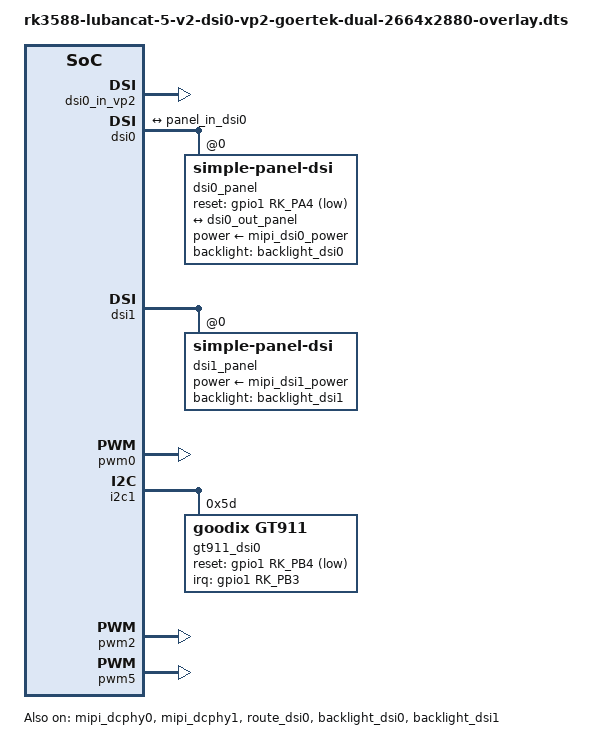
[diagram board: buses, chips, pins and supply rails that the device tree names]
/dts-v1/;
/plugin/;

#include <dt-bindings/gpio/gpio.h>
#include <dt-bindings/pinctrl/rockchip.h>
#include <dt-bindings/display/drm_mipi_dsi.h>
#include <dt-bindings/interrupt-controller/irq.h>

/ {
	fragment@0 {
		target = <&mipi_dcphy0>;

		__overlay__ {
			status = "okay";
		};
	};

	fragment@1 {
		target = <&mipi_dcphy1>;

		__overlay__ {
			status = "okay";
		};
	};

	fragment@2 {
		target = <&route_dsi0>;

		__overlay__ {
			status = "okay";
			connect = <&vp2_out_dsi0>;
		};
	};

	fragment@3 {
		target = <&route_dsi1>;

		__overlay__ {
			status = "disabled";
		};
	};

	fragment@4 {
		target = <&dsi0_in_vp2>;

		__overlay__ {
			status = "okay";
		};
	};

	fragment@5 {
		target = <&dsi1_in_vp3>;

		__overlay__ {
			status = "disabled";
		};
	};

	fragment@6 {
		target = <&dsi0>;

		__overlay__ {
			status = "okay";
			#address-cells = <1>;
			#size-cells = <0>;
			rockchip,dual-channel = <&dsi1>;
			rockchip,lane-rate = <1250000>;

			dsi0_panel: panel@0 {
				status = "okay";
				compatible = "simple-panel-dsi";
				reg = <0>;
				backlight = <&backlight_dsi0>;
				power-supply = <&mipi_dsi0_power>;
				reset-gpios = <&gpio1 RK_PA4 GPIO_ACTIVE_LOW>;

				enable-delay-ms = <35>;
				prepare-delay-ms = <6>;
				reset-delay-ms = <2000>;
				init-delay-ms = <3000>;
				unprepare-delay-ms = <0>;
				disable-delay-ms = <20>;

				dsi,flags = <(MIPI_DSI_MODE_VIDEO |
					       MIPI_DSI_MODE_VIDEO_BURST |
					       MIPI_DSI_CLOCK_NON_CONTINUOUS |
					       MIPI_DSI_MODE_LPM)>;
				dsi,format = <MIPI_DSI_FMT_RGB888>;
				dsi,lanes = <8>;

				panel-init-sequence = [
					39 00 02 b0 00
					39 00 02 ff 00
					39 00 5f f5 12 00 00 89 30 80 0f 00 0d e0 00 18 03 78 03 78 02 00 02 e1 00 20 02 b9 00 0c 00 0d 04 86 02 94 18 00 10 f0 03 0c 20 00 06 0b 0b 33 0e 1c 2a 38 46 54 62 69 70 77 79 7b 7d 7e 01 02 01 00 09 40 09 be 19 fc 19 fa 19 f8 1a 38 1a 78 1a b6 2a b6 2a f4 2a f4 4b 34 63 74 00 00 00 00 00 00
					39 00 5f f6 11 00 00 ab 10 a0 0a 00 05 a0 00 20 02 d0 03 84 01 9a 02 68 00 19 02 d9 00 0e 00 0f 03 df 02 eb 16 00 10 ec 07 10 20 00 06 0f 0f 33 0e 1c 2a 38 46 54 62 69 70 77 79 7b 7d 7e 01 c2 22 00 2a 40 2a be 3a fc 3a fa 3a f8 3b 38 3b 78 3b 76 4b b6 4b b6 4b f4 63 f4 7c 34 00 00 00 00 00 00
					39 00 5f f7 11 00 00 89 10 80 0a 00 05 a0 00 20 02 d0 02 d0 02 00 02 68 00 20 03 87 00 0a 00 0c 03 19 02 63 18 00 10 f0 03 0c 20 00 06 0b 0b 33 0e 1c 2a 38 46 54 62 69 70 77 79 7b 7d 7e 01 02 01 00 09 40 09 be 19 fc 19 fa 19 f8 1a 38 1a 78 1a b6 2a f6 2b 34 2b 74 3b 74 6b f4 00 00 00 00 00 00
					39 00 5f f8 11 00 00 ab 10 a0 0a 00 05 a0 00 20 02 d0 03 84 01 9a 02 68 00 19 02 d9 00 0e 00 0f 03 df 02 eb 16 00 10 ec 07 10 20 00 06 0f 0f 33 0e 1c 2a 38 46 54 62 69 70 77 79 7b 7d 7e 01 c2 22 00 2a 40 2a be 3a fc 3a fa 3a f8 3b 38 3b 78 3b 76 4b b6 4b b6 4b f4 63 f4 7c 34 00 00 00 00 00 00
					39 00 1c b1 00 18 19 00 18 18 00 18 18 00 18 18 00 18 18 00 18 18 00 18 18 00 18 18 00 18 19
					39 00 13 b2 0f 00 0f 00 0f 00 0f 00 0f 00 0f 00 0f 00 0f 00 0f 00
					39 00 03 b4 00 ba
					39 00 08 b5 11 11 00 01 25 00 eb
					39 00 02 b7 93
					39 00 02 b8 06
					39 00 02 ba 8c
					39 00 02 bb 01
					39 00 03 bc 00 00
					39 00 15 c7 00 00 ff ff 01 03 ff 03 ff 03 ff 00 00 00 00 00 00 00 00 00
					39 00 09 c8 10 32 54 76 98 ba dc 0e
					39 00 02 ff 01
					39 00 15 b1 30 6c 06 ff ff 00 00 48 a3 6b 00 92 03 1a d0 09 00 00 00 08
					39 00 04 b2 00 00 00
					39 00 bc b5 11 11 10 33 33 33 33 33 ff ff ff 6c 00 00 ff ff ff ff f0 01 00 fb 00 00 00 aa fa 1b 03 20 00 40 00 00 03 10 51 51 10 04 10 03 11 10 04 10 03 10 04 10 03 11 10 03 10 03 00 00 00 00 10 01 10 01 00 00 00 1f ff 00 00 10 01 10 01 00 00 00 1f ff 00 00 00 10 01 10 01 00 80 00 1f ff 00 00 00 10 01 10 01 00 00 00 1f ff 00 00 00 10 01 10 01 00 00 00 1f ff 00 00 10 01 10 01 00 00 00 1f ff 01 00 10 01 10 01 00 00 00 00 00 00 00 10 01 10 01 00 00 00 00 00 00 00 00 00 02 00 00 02 00 00 02 00 00 02 00 00 02 00 00 02 00 00 02 00 00 02 00 00 00 00 00 00 00 00 00 00 00 00
					39 00 55 b6 b0 00 00 00 00 00 80 04 0a f0 01 00 00 20 20 00 00 00 00 00 00 00 00 00 00 00 03 05 84 97 8b 00 00 21 00 21 00 21 00 21 00 21 00 21 00 40 00 00 00 00 00 00 00 00 00 00 00 00 00 00 00 00 00 00 00 00 00 00 00 00 03 28 00 14 00 14 00 14 00 14 00 14 00 14
					39 00 5d b7 00 00 00 02 00 00 40 05 00 00 88 88 88 88 00 00 00 00 00 00 00 00 00 00 00 00 00 00 00 00 00 00 00 00 00 00 00 00 00 a8 a8 a8 a8 a8 a8 a8 a8 00 ff aa 00 09 10 00 00 00 00 00 00 00 11 11 11 11 11 11 11 11 11 11 11 11 a0 00 00 10 09 c4 01 0a 0a 03 c9 00 00 00 06 7c 28 06 7c 28
					39 00 77 ba 00 00 00 00 20 02 6c 10 00 00 00 00 00 00 00 6c 10 00 00 00 00 01 50 17 00 10 00 00 00 00 00 00 00 00 00 00 00 00 00 00 00 00 00 00 00 00 00 00 00 0f ff 00 00 00 00 00 00 00 0f 10 00 10 00 00 00 00 01 b3 20 00 10 00 00 00 00 02 00 00 02 00 00 02 00 00 02 00 00 02 00 00 02 00 00 02 00 00 02 00 00 00 00 00 00 00 00 00 00 00 00 00 00 00 00 00 00 00 00 00
					39 00 78 bb 3f fd 00 1f 3f f0 00 03 3f fc 00 0f 3f fc 00 0f 3f fc 00 0f 3f fc 00 0f 3f f0 00 03 3f fc 00 0f 00 00 00 00 00 00 00 00 00 00 00 00 00 00 00 00 00 00 00 00 00 3f fc 00 0f 3f fc 00 0f 3f fc 00 0f 3f fc 00 0f 3f fc 00 0f 3f fc 00 0f 3f fc 00 0f 3f fd 15 5f 3f fc 00 0f 3f fc 00 0f 3f fc 00 0f 3f fc 00 0f 03 c0 00 0f 00 00 48 00 00 01 00 09 3f fc 00 0f 00 00
					39 00 21 be 00 00 00 00 00 07 00 00 00 00 00 00 00 00 00 00 50 aa aa aa aa aa aa 90 00 aa aa aa aa aa aa 90
					39 00 8c bf 46 48 4a 4c 4e 50 02 06 0a 0e 12 16 1a 1e 22 2a 01 01 01 01 3c 41 00 00 01 01 33 00 01 01 46 48 4a 4c 4e 50 02 06 0a 0e 12 16 1a 1e 22 2a 01 01 01 01 3c 41 00 00 01 01 33 01 01 01 00 00 00 00 00 00 00 00 00 00 00 00 00 00 00 00 00 00 00 00 00 00 00 00 ff ff ff ff ff ff ff 0f 3f 00 01 00 00 08 c0 0f 00 20 00 00 00 08 00 00 80 00 00 00 00 00 00 00 00 00 00 00 00 00 00 00 00 00 00 00 00 00 00 00 00 00 00 00 00 00 00
					39 00 69 c0 03 e8 03 e8 03 e8 00 07 00 07 00 07 03 e8 03 e8 03 e8 00 07 00 07 00 07 03 e8 03 e8 03 e8 00 07 00 07 00 07 03 e8 03 e8 03 e8 00 07 00 07 00 07 00 00 00 29 00 17 00 17 00 17 00 17 00 17 00 17 00 00 00 00 00 00 00 00 00 00 00 00 00 00 00 2b 00 16 00 16 00 16 00 16 00 16 00 08 00 00 00 00 00 00 00 00 00 00 00 00
					39 00 54 c2 00 00 bc 00 97 00 97 00 00 00 00 00 00 00 00 00 00 00 5e 00 5e 00 5e 00 5e 00 5e 00 5e 00 5e 00 5e 00 9b 00 9b 00 a3 00 ab 00 31 00 bc 00 31 00 bc 00 0e 00 31 00 0e 00 31 00 84 00 b4 00 00 00 9f 00 00 1f ff 00 00 1f ff 00 26 00 84 00 5e 00 5e 00 00
					39 00 ac c3 02 00 14 02 00 14 02 00 14 02 00 14 02 00 14 02 00 14 00 00 12 00 00 12 00 00 12 00 00 12 00 00 12 00 00 12 06 00 24 06 00 24 06 00 24 06 00 24 06 00 24 06 00 24 03 00 28 03 00 28 03 00 28 03 00 28 03 00 28 03 00 28 00 00 00 60 00 24 00 82 00 58 00 99 00 4c 00 aa 00 2e 00 9f 00 26 00 58 00 29 00 84 00 00 00 00 00 00 00 02 00 19 00 21 00 a3 00 ab 00 00 00 00 00 00 00 00 00 00 00 00 00 00 00 00 00 00 00 00 00 00 00 00 00 00 00 00 00 00 00 00 00 00 00 00 00 00 00 00 00 00 00 00 10 00 00 00 00 00 00 00 00 00 00
					39 00 2b c4 00 00 00 00 00 00 5e 00 5f 00 7e 00 81 00 57 00 57 00 4b 00 4b 00 28 00 03 00 5a 00 00 00 5e 00 5e 00 5e 00 5e f0 ff ff 7f e7
					39 00 0b c5 00 00 00 00 00 00 00 00 08 00
					39 00 36 c7 51 c8 c8 c8 c8 c8 c8 c8 c8 c8 00 ff ff ff ff ff ff ff ff ff 4a 48 46 44 42 40 3e 3c 3a 00 ff ff ff ff ff ff ff ff ff ff ff ff ff ff ff ff ff ff 04 04 42 00 88
					39 00 44 c8 00 1c fc fc fc 00 00 00 00 00 00 00 00 00 00 00 00 00 00 00 00 00 00 00 00 00 00 00 00 00 00 00 00 00 00 00 00 00 00 00 00 00 00 00 00 00 00 00 00 00 00 00 00 00 00 00 00 00 00 00 00 00 00 00 00 08 08
					39 00 44 c9 00 1c fc fc fc 00 00 00 00 00 00 00 00 00 00 00 00 00 00 00 00 00 00 00 00 00 00 00 00 00 00 00 00 00 00 00 00 00 00 00 00 00 00 00 00 00 00 00 00 00 00 00 00 00 00 00 00 00 00 00 00 00 00 00 00 08 08
					39 00 44 ca c0 1c fc fc fc 00 00 00 00 00 00 00 00 00 00 00 00 00 00 00 00 00 00 00 00 00 00 00 00 00 00 00 00 00 00 00 00 00 00 00 00 00 00 00 00 00 00 00 00 00 00 00 00 00 00 00 00 00 00 00 00 00 00 00 00 08 08
					39 00 3d cb 91 cf ed 52 54 04 32 33 ff ff ff ff ff ff ff ff ff f8 00 00 00 01 01 02 02 03 03 04 04 04 04 04 04 04 04 04 04 04 04 04 0a 0b 0b 0c 0c 0d 0d 0e 0e 0e 0e 0e 0e 0e 0e 0e 0e 0e 0e 0e
					39 00 25 cc 8d e0 01 32 32 32 32 32 32 32 32 32 00 49 81 2c 00 40 00 08 0c 00 40 40 00 00 00 00 00 00 00 02 00 ff ff ff
					39 00 0f ce 00 00 00 00 00 00 00 00 00 00 00 00 00 00
					39 00 13 cf 88 24 00 00 00 00 00 00 00 00 00 00 00 00 00 00 00 00
					39 00 b2 d1 0c ff ff ff 00 03 0c 1e 38 5b 89 c0 ff 00 03 0c 1e 38 5b 89 c0 ff 00 03 0c 1e 38 5b 89 c0 ff ff ff ff ff ff ff ff ff ff ff ff ff ff ff ff ff ff ff ff ff ff ff ff ff ff ff ff ff ff ff ff ff ff ff ff 80 80 80 80 80 80 80 80 80 80 80 80 80 80 80 80 80 80 80 80 80 80 80 80 80 80 80 80 80 80 80 80 80 80 80 80 80 80 80 80 80 80 80 80 80 80 80 80 80 80 80 00 00 00 00 00 00 00 00 00 00 00 00 00 00 00 00 00 00 00 00 00 00 00 00 00 00 00 00 00 00 00 00 00 00 00 00 00 00 00 00 00 00 00 00 00 00 00 00 00 00 00 ff ff 00 17 bb 04 38 00 00
					39 00 10 d2 2a 00 4d 8b 4d 8b 4d 8b 08 00 08 00 08 00 00
					39 00 6a d3 00 40 08 01 00 20 03 00 40 06 00 80 0a 00 c0 0e 01 00 12 01 40 18 01 c0 20 02 40 28 02 c0 30 03 40 38 00 00 40 08 01 00 20 03 00 40 06 00 80 0a 00 c0 0e 01 00 12 01 40 18 01 c0 20 02 40 28 02 c0 30 03 40 38 00 00 40 08 01 00 20 03 00 40 06 00 80 0a 00 c0 0e 01 00 12 01 40 18 01 c0 20 02 40 28 02 c0 30 03 40 38 00
					39 00 07 d6 00 ff df bf 9f 7f
					39 00 11 d9 02 0a 0a 0a 0a 0a 0a 00 00 00 00 00 00 00 00 00
					39 00 06 de 14 14 14 2a 02
					39 00 3f e1 00 2e 35 07 df df 18 18 0e 1d 0e 0e 0e 0e 1f 1f 37 37 33 33 33 33 f1 00 00 00 00 00 00 00 2e 33 07 df df 0e 0e 0e 0e 0e 0e 0e 0e 1f 1f 33 33 33 33 33 33 f1 00 00 00 00 00 00 00 00 00 00
					39 00 94 e3 06 11 03 33 33 55 f3 80 94 00 68 00 08 70 10 00 00 00 00 00 00 00 00 00 00 00 00 00 00 00 00 00 00 00 00 00 00 00 00 00 00 00 00 00 00 00 00 00 00 00 00 00 00 00 00 00 00 00 00 00 00 00 00 00 00 00 00 00 00 00 00 00 00 00 00 00 00 00 00 00 00 00 00 00 00 00 00 00 00 00 00 00 00 00 00 00 00 00 00 00 00 00 00 00 00 00 00 00 00 00 00 00 00 00 00 00 00 00 00 00 00 00 00 00 00 00 00 00 00 00 00 00 00 00 00 00 00 00 00 00 00 00 00 00
					39 00 1a e4 00 d2 b7 9d 1d 79 04 d2 00 2c 40 00 00 05 1f 1f 1f 1f 1f 1f 00 00 00 00 00
					39 00 49 e5 08 08 00 01 00 02 03 01 04 04 05 05 05 05 05 06 06 07 08 02 02 03 0c 10 08 0c 02 10 08 08 08 08 00 00 04 08 1c 1c 1c 08 08 08 08 08 08 08 08 08 08 08 08 08 08 1c 1c 1c 08 04 40 8c cc cc c8 cc cc cc cc cc cc c4 00 00
					39 00 06 ea 02 00 00 00 00
					39 00 12 ec 60 03 03 12 12 00 57 00 78 08 00 00 01 00 10 00 00
					39 00 02 ed 00
					39 00 02 ff 03
					39 00 3d b1 ff ff ff ff ff ff ff ff ff ff ff ff ff ff ff ff ff ff ff ff ff ff ff ff ff ff ff ff ff ff ff ff ff ff ff ff ff ff ff ff ff ff ff ff ff ff ff ff ff ff ff ff ff ff ff ff ff ff ff ff ff
					39 00 3d b3 22 c2 2c 22 c2 0d 20 d1 eb 1e b1 d3 1d 31 ba 23 c2 3c 23 c2 21 22 12 03 20 31 ef 1e f1 d5 25 e2 5e 25 e2 47 24 72 33 23 32 25 22 52 18 23 c2 3c 23 c2 21 22 12 03 20 31 ef 1e f1 d5
					39 00 3d b4 33 23 32 33 23 32 33 23 32 33 23 32 33 23 32 33 23 32 33 23 32 33 23 32 33 23 32 33 23 32 33 23 32 33 23 32 33 23 32 33 23 32 33 23 32 33 23 32 33 23 32 33 23 32 33 23 32 33 23 32
					39 00 3d b6 00 00 00 00 00 00 00 00 00 00 00 00 00 00 00 00 00 00 00 00 00 00 00 00 00 00 00 33 3f ff 00 00 00 00 00 00 00 00 00 00 00 00 00 00 00 00 00 00 00 00 00 00 00 00 00 00 00 33 3f ff
					39 00 72 c0 00 04 80 49 04 b0 4f 05 3a 58 36 0a 67 d6 eb 74 c7 91 7d 08 09 84 18 a1 90 09 4b 98 d9 d2 a1 8a 53 a9 3a d2 b4 c0 00 45 a4 6a 48 a4 ca 50 b5 58 5d a6 4c 6b c7 1d 76 b7 b5 7f 78 30 8a 49 03 95 d9 a9 9f 1a 39 a8 0a c2 b0 3b 81 00 04 6d 48 54 b5 51 55 7f 5d a6 65 6d 97 36 78 27 c5 7f d8 34 86 38 c2 91 39 60 9a 69 ec a2 fa 70 aa fa ed b6 80
					39 00 72 c1 00 04 75 48 94 b1 50 15 5e 5a a6 3d 6b c7 27 78 27 cc 80 a8 44 88 38 e8 94 39 91 9d ca 24 a6 ba b0 af db 36 bc 10 00 46 f4 7f 49 f4 df 52 b5 78 60 86 88 6f 67 5b 7b 17 f9 83 48 7c 8e e9 54 9a c9 fe a4 ca 9c ae 8b 31 b7 5c 0a 00 04 73 48 f4 c7 53 75 a7 60 26 97 70 c7 66 7b 57 fa 83 68 6d 8a 19 02 95 a9 ab 9f 8a 43 a8 9a d2 b1 8b 5b be 40
					39 00 72 c2 00 04 84 49 84 c0 51 05 66 5c 36 51 6d a7 4a 79 e7 e7 82 d8 6b 8a 39 0c 96 39 b8 a0 aa 56 a9 ba e7 b2 eb 78 c0 a0 00 47 c4 8c 4a c4 ec 53 95 8e 62 06 a8 71 a7 7b 7d 28 10 86 48 a6 91 89 79 9d 6a 2b a7 ea ce b1 db 6d bb 6c 4d 00 04 83 49 f4 d7 54 75 be 61 b6 b1 72 67 81 7c f8 13 84 d8 8c 8c 49 23 97 a9 d2 a2 4a 71 ab eb 07 b5 1b 9b c3 d0
					39 00 72 c3 00 04 97 4a b4 d3 52 35 7b 5d d6 70 6f 67 63 7c 18 0a 84 c8 8f 8c b9 39 99 49 e3 a3 ba 8f ad 7b 26 b7 5b c4 c6 60 00 46 d4 81 4a 94 f9 54 e5 ad 64 16 c7 73 e7 a8 7f 58 42 88 c8 cc 94 29 af a0 aa 66 ab cb 10 b6 2b b5 c0 5c b0 00 04 94 4b 04 e8 55 85 d1 63 66 ce 73 e7 9f 7f 08 36 87 68 b1 8e 69 4c 9a da 02 a5 6a aa af bb 4a b9 8b eb c8 f0
					39 00 72 c4 00 04 83 49 b4 cb 52 b5 95 5e a6 93 71 c7 83 7d a8 2c 87 18 b7 8f 29 58 9b 2a 12 a6 2a bb b1 0b 61 ba fc 04 cc 10 00 45 a4 72 4a 25 02 56 65 b5 65 e6 e9 76 07 c0 81 88 6b 8b 38 f2 96 c9 da a3 9a 94 ae cb 46 b9 cb f5 c4 9d 10 00 04 a6 4c 24 fa 56 a5 e8 64 86 e6 75 c7 b9 80 98 4f 89 28 cf 90 89 6f 9d 0a 2d a8 2a de b2 eb 83 bd 7c 2e ce c0
					39 00 72 c5 00 01 af 31 93 7f 3e 84 33 47 14 cf 53 55 7c 5b f6 03 64 46 bb 72 a7 95 80 28 73 8e 89 67 9f 4a 82 b2 2b db ca 90 00 00 52 70 2d 93 3b 39 63 e4 45 04 c4 51 b5 6e 5b f6 0b 69 27 0f 78 57 f7 86 d8 e3 96 09 ea a7 3b 0e bc 0c 7d 00 00 5a 19 62 21 2b d3 4b 3c 14 5f 4e 35 3f 59 35 e3 62 d6 b0 72 87 9a 80 d8 81 8f 69 73 9f fa 88 b2 3b d2 c9 00
					39 00 72 c6 00 01 af 31 93 7f 3e 84 33 47 14 cf 53 55 7c 5b f6 03 64 46 bb 72 a7 95 80 28 73 8e 89 67 9f 4a 82 b2 2b db ca 90 00 00 52 70 2d 93 3b 39 63 e4 45 04 c4 51 b5 6e 5b f6 0b 69 27 0f 78 57 f7 86 d8 e3 96 09 ea a7 3b 0e bc 0c 7d 00 00 5a 19 62 21 2b d3 4b 3c 14 5f 4e 35 3f 59 35 e3 62 d6 b0 72 87 9a 80 d8 81 8f 69 73 9f fa 88 b2 3b d2 c9 00
					39 00 72 c7 00 01 af 31 93 7f 3e 84 33 47 14 cf 53 55 7c 5b f6 03 64 46 bb 72 a7 95 80 28 73 8e 89 67 9f 4a 82 b2 2b db ca 90 00 00 52 70 2d 93 3b 39 63 e4 45 04 c4 51 b5 6e 5b f6 0b 69 27 0f 78 57 f7 86 d8 e3 96 09 ea a7 3b 0e bc 0c 7d 00 00 5a 19 62 21 2b d3 4b 3c 14 5f 4e 35 3f 59 35 e3 62 d6 b0 72 87 9a 80 d8 81 8f 69 73 9f fa 88 b2 3b d2 c9 00
					39 00 72 c8 00 01 af 31 93 7f 3e 84 33 47 14 cf 53 55 7c 5b f6 03 64 46 bb 72 a7 95 80 28 73 8e 89 67 9f 4a 82 b2 2b db ca 90 00 00 52 70 2d 93 3b 39 63 e4 45 04 c4 51 b5 6e 5b f6 0b 69 27 0f 78 57 f7 86 d8 e3 96 09 ea a7 3b 0e bc 0c 7d 00 00 5a 19 62 21 2b d3 4b 3c 14 5f 4e 35 3f 59 35 e3 62 d6 b0 72 87 9a 80 d8 81 8f 69 73 9f fa 88 b2 3b d2 c9 00
					39 00 72 c9 00 01 af 31 93 7f 3e 84 33 47 14 cf 53 55 7c 5b f6 03 64 46 bb 72 a7 95 80 28 73 8e 89 67 9f 4a 82 b2 2b db ca 90 00 00 52 70 2d 93 3b 39 63 e4 45 04 c4 51 b5 6e 5b f6 0b 69 27 0f 78 57 f7 86 d8 e3 96 09 ea a7 3b 0e bc 0c 7d 00 00 5a 19 62 21 2b d3 4b 3c 14 5f 4e 35 3f 59 35 e3 62 d6 b0 72 87 9a 80 d8 81 8f 69 73 9f fa 88 b2 3b d2 c9 00
					39 00 72 ca 00 02 b2 2c a2 fa 35 a3 bc 40 d4 c0 53 b5 a5 60 06 58 6a 16 ea 72 27 94 7e d8 45 89 38 dd 91 e9 5e 99 c9 d4 a4 a0 00 2a 72 bb 2e 33 33 38 73 d1 46 e4 f0 55 d5 bd 61 26 61 6a b6 ec 76 37 c6 82 38 76 8c c9 15 95 a9 9e 9d fa 60 00 02 60 28 02 c0 34 03 c6 43 d5 01 58 25 ea 64 36 93 6d 67 13 74 97 aa 7f b8 4c 89 48 d7 91 79 56 99 19 cd a4 00
					39 00 72 cb 00 02 cd 2e 53 15 37 53 db 44 34 ef 57 45 e9 64 b6 a0 6f 07 31 76 f7 e0 84 18 97 8e 99 35 97 c9 c3 a0 2a 45 ac b0 00 2b f2 d3 2f b3 4b 3a 23 fe 49 f5 27 59 c6 04 65 96 b1 6f b7 3c 7b 48 1b 87 e8 d7 92 b9 78 9c 2a 08 a5 2a e0 00 02 62 28 62 ce 35 e3 f2 47 95 35 5b d6 27 68 56 d0 71 57 52 78 a7 ee 84 78 97 8e 39 2c 97 09 b2 9f 3a 35 ab 90
					39 00 72 cc 00 02 dc 2f 43 24 38 43 ef 45 75 08 59 36 02 66 e6 c8 70 e7 56 79 57 ff 86 88 c3 91 29 61 9a 99 f2 a3 7a 80 b0 c0 00 2c b2 df 30 73 57 3b 44 13 4c 35 4c 5b f6 26 68 56 d3 71 e7 60 7d 88 4b 8a c9 09 95 c9 ad 9f aa 44 a9 1b 23 00 02 79 29 d2 e5 37 54 0d 49 25 52 5d 86 47 6a 26 f3 73 47 73 7a b8 0f 86 a8 c2 90 b9 57 9a 09 e5 a2 ba 6f af 60
					39 00 72 cd 00 02 cd 2e 93 21 39 14 04 47 35 29 5b b6 2e 69 56 f3 74 17 86 7c 58 35 89 98 f8 94 b9 9b 9e 8a 34 a8 2a cf b6 50 00 2b 92 d1 30 13 61 3c b4 2b 4e 15 74 5e 86 50 6b 27 05 75 17 96 81 08 81 8e 99 44 99 b9 f0 a4 3a 92 ae 4b 85 00 02 76 29 e2 ee 38 e4 30 4b 45 77 5f c6 6e 6c 87 16 75 e7 9b 7d 58 3b 89 98 f0 94 39 91 9d 9a 28 a7 2a bc b5 20
					39 00 72 ce 00 02 db 2f 73 2f 39 f4 17 48 f5 49 5d 36 50 6b b7 0c 75 c7 a2 7e 08 53 8c 29 1c 97 29 c8 a1 3a 68 ab 8b 08 ba e0 00 2c 52 dd 30 d3 6d 3d 94 48 4f e5 8b 60 76 76 6d 17 25 77 47 ba 83 68 aa 91 19 6f 9c ba 20 a7 8a cc b1 db cf 00 02 8a 2b 23 02 3a 24 49 4d 05 8d 61 46 89 6e 57 33 77 97 b7 7f 08 5b 8b e9 14 96 99 ba a0 8a 58 aa 8a f5 b9 70
					39 00 72 cf 00 01 af 31 93 7f 3e 84 33 47 14 cf 53 55 7c 5b f6 03 64 46 bb 72 a7 95 80 28 73 8e 89 67 9f 4a 82 b2 2b db ca 90 00 00 52 70 2d 93 3b 39 63 e4 45 04 c4 51 b5 6e 5b f6 0b 69 27 0f 78 57 f7 86 d8 e3 96 09 ea a7 3b 0e bc 0c 7d 00 00 5a 19 62 21 2b d3 4b 3c 14 5f 4e 35 3f 59 35 e3 62 d6 b0 72 87 9a 80 d8 81 8f 69 73 9f fa 88 b2 3b d2 c9 00
					39 00 72 d0 00 01 af 31 93 7f 3e 84 33 47 14 cf 53 55 7c 5b f6 03 64 46 bb 72 a7 95 80 28 73 8e 89 67 9f 4a 82 b2 2b db ca 90 00 00 52 70 2d 93 3b 39 63 e4 45 04 c4 51 b5 6e 5b f6 0b 69 27 0f 78 57 f7 86 d8 e3 96 09 ea a7 3b 0e bc 0c 7d 00 00 5a 19 62 21 2b d3 4b 3c 14 5f 4e 35 3f 59 35 e3 62 d6 b0 72 87 9a 80 d8 81 8f 69 73 9f fa 88 b2 3b d2 c9 00
					39 00 72 d1 00 01 af 31 93 7f 3e 84 33 47 14 cf 53 55 7c 5b f6 03 64 46 bb 72 a7 95 80 28 73 8e 89 67 9f 4a 82 b2 2b db ca 90 00 00 52 70 2d 93 3b 39 63 e4 45 04 c4 51 b5 6e 5b f6 0b 69 27 0f 78 57 f7 86 d8 e3 96 09 ea a7 3b 0e bc 0c 7d 00 00 5a 19 62 21 2b d3 4b 3c 14 5f 4e 35 3f 59 35 e3 62 d6 b0 72 87 9a 80 d8 81 8f 69 73 9f fa 88 b2 3b d2 c9 00
					39 00 72 d2 00 01 af 31 93 7f 3e 84 33 47 14 cf 53 55 7c 5b f6 03 64 46 bb 72 a7 95 80 28 73 8e 89 67 9f 4a 82 b2 2b db ca 90 00 00 52 70 2d 93 3b 39 63 e4 45 04 c4 51 b5 6e 5b f6 0b 69 27 0f 78 57 f7 86 d8 e3 96 09 ea a7 3b 0e bc 0c 7d 00 00 5a 19 62 21 2b d3 4b 3c 14 5f 4e 35 3f 59 35 e3 62 d6 b0 72 87 9a 80 d8 81 8f 69 73 9f fa 88 b2 3b d2 c9 00
					39 00 72 d3 00 01 af 31 93 7f 3e 84 33 47 14 cf 53 55 7c 5b f6 03 64 46 bb 72 a7 95 80 28 73 8e 89 67 9f 4a 82 b2 2b db ca 90 00 00 52 70 2d 93 3b 39 63 e4 45 04 c4 51 b5 6e 5b f6 0b 69 27 0f 78 57 f7 86 d8 e3 96 09 ea a7 3b 0e bc 0c 7d 00 00 5a 19 62 21 2b d3 4b 3c 14 5f 4e 35 3f 59 35 e3 62 d6 b0 72 87 9a 80 d8 81 8f 69 73 9f fa 88 b2 3b d2 c9 00
					39 00 02 ff 01
					39 00 02 ec 20
					39 00 02 ff 00
					39 00 0f 3b 00 08 00 08 00 00 06 18 05 a0 04 c8 03 a0
					39 00 02 03 01
					39 00 02 26 01
					39 00 03 44 00 00
					39 00 02 35 00
					39 00 02 36 02
					39 00 03 51 ff ff
					39 00 02 53 20
					39 00 02 64 00
					39 00 02 65 90
					39 00 02 ff 01
					39 00 02 b0 04
					39 00 03 c5 02 03
					39 00 72 f5 12 00 00 ab 30 80 0b 40 0a 68 05 a0 02 9a 02 9a 02 00 02 a1 00 20 85 ee 00 09 00 0f 00 16 00 0f 18 00 10 f0 07 10 20 00 06 0f 0f 33 0e 1c 2a 38 46 54 62 69 70 77 79 7b 7d 7e 02 02 22 00 2a 40 2a be 3a fc 3a fa 3a f8 3b 38 3b 78 3b b6 4b b6 4b f4 4b f4 6c 34 84 74 00 00 00 00 00 00 00 00 00 00 00 00 00 00 00 00 00 00 00 00 00 00 00 00 00
					39 00 02 ff 00
					39 00 02 b0 00
					05 78 01 29
					05 78 01 11
					0a 00 80 12 00 00 ab 30 80 0b 40 0a 68 05 a0 02 9a 02 9a 02 00 02 a1 00 20 85 ee 00 09 00 0f 00 16 00 0f 18 00 10 f0 07 10 20 00 06 0f 0f 33 0e 1c 2a 38 46 54 62 69 70 77 79 7b 7d 7e 02 02 22 00 2a 40 2a be 3a fc 3a fa 3a f8 3b 38 3b 78 3b b6 4b b6 4b f4 4b f4 6c 34 84 74 00 00 00 00 00 00 00 00 00 00 00 00 00 00 00 00 00 00 00 00 00 00 00 00 00 00 00 00 00 00 00 00 00 00 00 00 00 00 00 00
				];

				panel-exit-sequence = [
					05 78 01 28
					05 00 01 10
				];

				compressed-data;
				slice-width = <666>;
				slice-height = <1440>;
				version-major = <1>;
				version-minor = <1>;

				disp0_timings0: display-timings {
					native-mode = <&dsi0_timing0>;
					dsi0_timing0: timing0 {
						clock-frequency = <856000000>;
						hactive = <2664>;
						vactive = <2880>;
						hback-porch = <200>;
						hfront-porch = <400>;
						hsync-len = <4>;
						vback-porch = <10>;
						vfront-porch = <30>;
						vsync-len = <1>;
						hsync-active = <0>;
						vsync-active = <0>;
						de-active = <0>;
						pixelclk-active = <0>;
					};
				};

				ports {
					#address-cells = <1>;
					#size-cells = <0>;
					port@0 {
						reg = <0>;
						panel_in_dsi0: endpoint {
							remote-endpoint = <&dsi0_out_panel>;
						};
					};
				};
			};

			ports {
				#address-cells = <1>;
				#size-cells = <0>;

				port@1 {
					reg = <1>;
					dsi0_out_panel: endpoint {
						remote-endpoint = <&panel_in_dsi0>;
					};
				};
			};
		};
	};

	fragment@7 {
		target = <&dsi1>;

		__overlay__ {
			status = "okay";
			#address-cells = <1>;
			#size-cells = <0>;

			dsi1_panel: panel@0 {
				status = "okay";
				compatible = "simple-panel-dsi";
				reg = <0>;
				backlight = <&backlight_dsi1>;
				power-supply = <&mipi_dsi1_power>;

				enable-delay-ms = <35>;
				prepare-delay-ms = <6>;
				reset-delay-ms = <2000>;
				init-delay-ms = <3000>;
				unprepare-delay-ms = <0>;
				disable-delay-ms = <20>;

				dsi,flags = <(MIPI_DSI_MODE_VIDEO |
					       MIPI_DSI_MODE_VIDEO_BURST |
					       MIPI_DSI_CLOCK_NON_CONTINUOUS |
					       MIPI_DSI_MODE_LPM)>;
				dsi,format = <MIPI_DSI_FMT_RGB888>;
				dsi,lanes = <8>;

				compressed-data;
				slice-width = <666>;
				slice-height = <1440>;
				version-major = <1>;
				version-minor = <1>;
			};
		};
	};

	fragment@8 {
		target = <&pwm0>;

		__overlay__ {
			pinctrl-0 = <&pwm0m0_pins>;
			status = "okay";
		};
	};

	fragment@9 {
		target = <&i2c1>;

		__overlay__ {
			status = "okay";
			#address-cells = <1>;
			#size-cells = <0>;
			pinctrl-names = "default";
			pinctrl-0 = <&i2c1m2_xfer>;

			gt911_dsi0: gt911@5d {
				status = "okay";
				compatible = "goodix,gt911";
				reg = <0x5d>;
				interrupt-parent = <&gpio1>;
				interrupts = <RK_PB3 IRQ_TYPE_LEVEL_LOW>;
				reset-gpios = <&gpio1 RK_PB4 GPIO_ACTIVE_LOW>;
				irq-gpios = <&gpio1 RK_PB3 GPIO_ACTIVE_HIGH>;
				touchscreen-inverted-x = <1>;
				touchscreen-inverted-y = <1>;
			};
		};
	};

	fragment@10 {
		target = <&backlight_dsi0>;

		__overlay__ {
			status = "okay";
		};
	};

	fragment@11 {
		target = <&pwm2>;

		__overlay__ {
			status = "okay";
		};
	};

	fragment@12 {
		target = <&backlight_dsi1>;

		__overlay__ {
			status = "okay";
		};
	};

	fragment@13 {
		target = <&pwm5>;

		__overlay__ {
			status = "okay";
		};
	};
};
